# N32G05x register map
Vendor: Nationstech Ltd.; File version: 1.0
Registers are 32-bit, read-write, reset 0x0 unless marked. A register's access mark holds for its fields unless they carry their own. Offsets are from the block's base; [hi:lo] are bit positions; {n}, {i} and the like mark numbered series.

## AFIO — Alternate function I/O
Base 0x40010000
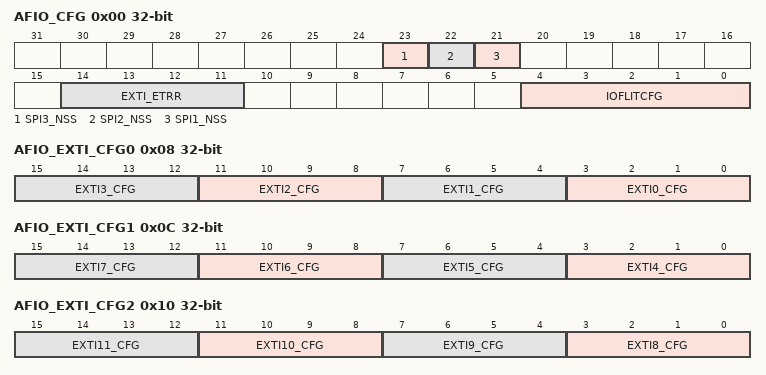
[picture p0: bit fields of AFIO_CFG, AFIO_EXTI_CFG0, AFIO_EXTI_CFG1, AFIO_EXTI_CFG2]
0x00 AFIO_CFG (reset mask 0xFFF800)
  [23] SPI3_NSS, [22] SPI2_NSS, [21] SPI1_NSS, [14:11] EXTI_ETRR, [4:0] IOFLITCFG
0x08 AFIO_EXTI_CFG0
  [4n+3:4n] EXTI{n}_CFG (n=0..3)
0x0C AFIO_EXTI_CFG1
  [4n-13:4n-16] EXTI{n}_CFG (n=4..7)
0x10 AFIO_EXTI_CFG2
  [4n-29:4n-32] EXTI{n}_CFG (n=8..11)
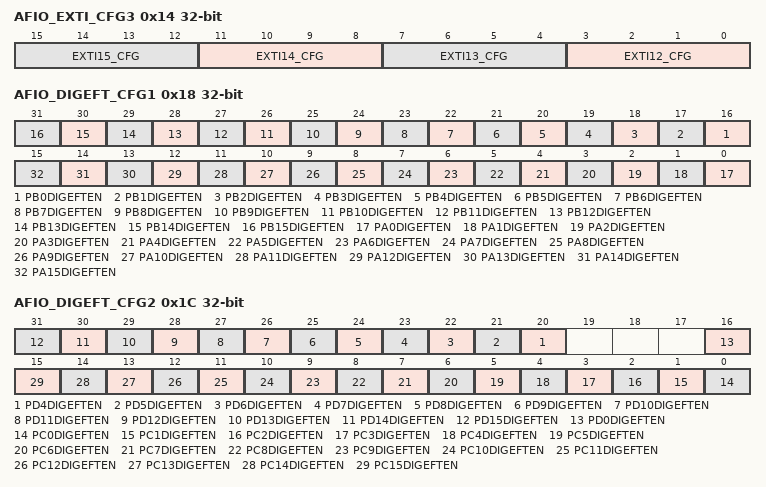
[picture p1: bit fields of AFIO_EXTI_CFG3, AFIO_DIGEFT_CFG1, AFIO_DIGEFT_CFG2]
0x14 AFIO_EXTI_CFG3
  [4n-45:4n-48] EXTI{n}_CFG (n=12..15)
0x18 AFIO_DIGEFT_CFG1
  [n+16] PB{n}DIGEFTEN (n=0..15), [n] PA{n}DIGEFTEN (n=0..15)
0x1C AFIO_DIGEFT_CFG2
  [n+16] PD{n}DIGEFTEN (n=4..15), [16] PD0DIGEFTEN, [n] PC{n}DIGEFTEN (n=0..15)

## I2C1 — Inter integrated circuit
Base 0x40005400
Same registers: I2C2 0x40005800
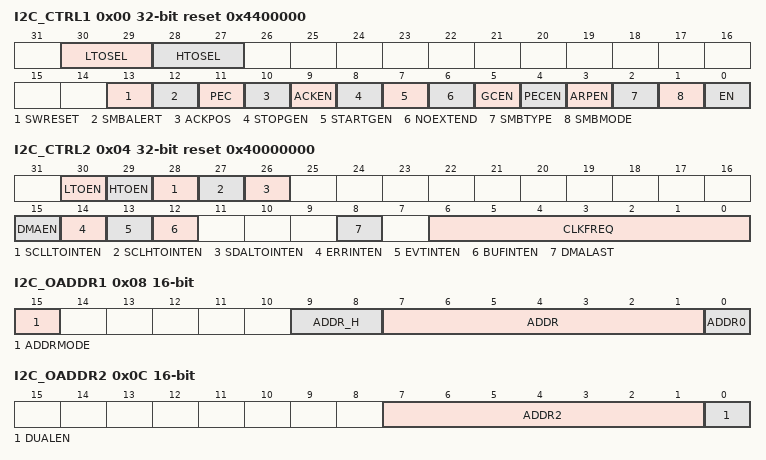
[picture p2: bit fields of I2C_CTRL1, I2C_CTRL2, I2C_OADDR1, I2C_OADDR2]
0x00 I2C_CTRL1 reset 0x4400000
  [30:29] LTOSEL, [28:27] HTOSEL, [13] SWRESET, [12] SMBALERT, [11] PEC, [10] ACKPOS, [9] ACKEN, [8] STOPGEN, [7] STARTGEN, [6] NOEXTEND, [5] GCEN, [4] PECEN, [3] ARPEN, [2] SMBTYPE, [1] SMBMODE, [0] EN
0x04 I2C_CTRL2 reset 0x40000000
  [30] LTOEN, [29] HTOEN, [28] SCLLTOINTEN, [27] SCLHTOINTEN, [26] SDALTOINTEN, [15] DMAEN, [14] ERRINTEN, [13] EVTINTEN, [12] BUFINTEN, [8] DMALAST, [6:0] CLKFREQ
0x08 I2C_OADDR1 16-bit
  [15] ADDRMODE, [9:8] ADDR_H, [7:1] ADDR, [0] ADDR0
0x0C I2C_OADDR2 16-bit
  [7:1] ADDR2, [0] DUALEN
0x10 I2C_DAT 16-bit
  [7:0] DATA
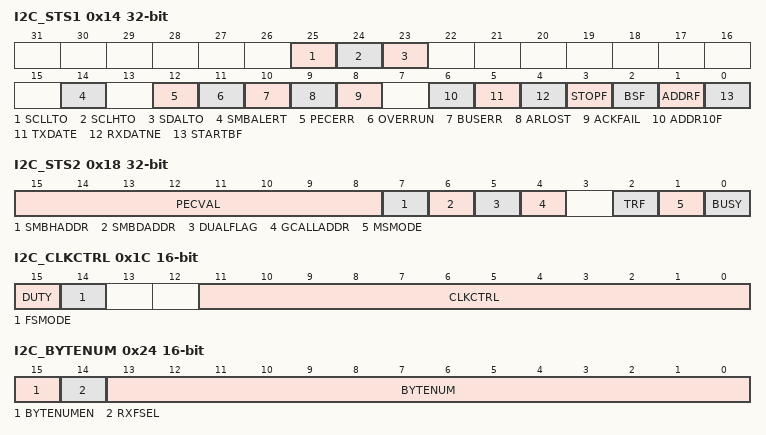
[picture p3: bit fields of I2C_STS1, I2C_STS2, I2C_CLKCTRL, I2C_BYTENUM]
0x14 I2C_STS1
  [25] SCLLTO, [24] SCLHTO, [23] SDALTO, [14] SMBALERT, [12] PECERR, [11] OVERRUN, [10] BUSERR, [9] ARLOST, [8] ACKFAIL, [6] ADDR10F, [5] TXDATE, [4] RXDATNE, [3] STOPF, [2] BSF, [1] ADDRF, [0] STARTBF
0x18 I2C_STS2
  [15:8] PECVAL, [7] SMBHADDR, [6] SMBDADDR, [5] DUALFLAG, [4] GCALLADDR, [2] TRF, [1] MSMODE, [0] BUSY
0x1C I2C_CLKCTRL 16-bit
  [15] DUTY, [14] FSMODE, [11:0] CLKCTRL
0x20 I2C_TMRISE 16-bit
  [5:0] TMRISE
0x24 I2C_BYTENUM 16-bit (reset mask 0xFF)
  [15] BYTENUMEN, [14] RXFSEL, [13:0] BYTENUM
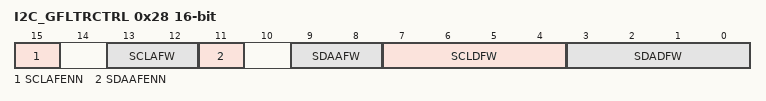
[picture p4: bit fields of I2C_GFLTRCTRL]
0x28 I2C_GFLTRCTRL 16-bit
  [15] SCLAFENN, [13:12] SCLAFW, [11] SDAAFENN, [9:8] SDAAFW, [7:4] SCLDFW, [3:0] SDADFW

## IWDG — Independent watchdog
Base 0x40003000
0x00 IWDG_KEY
  [15:0] KEYV
0x04 IWDG_PREDIV
  [2:0] PD
0x08 IWDG_RELV reset 0xFFF
  [11:0] REL
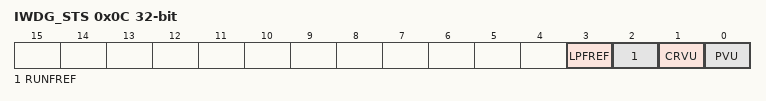
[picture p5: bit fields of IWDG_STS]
0x0C IWDG_STS (reset mask 0x3)
  [3] LPFREF, [2] RUNFREF, [1] CRVU, [0] PVU
0x10 IWDG_FREEZE
  [15:0] LPRERV

## LCD — Liquid Crystal Display
Base 0x40003C00
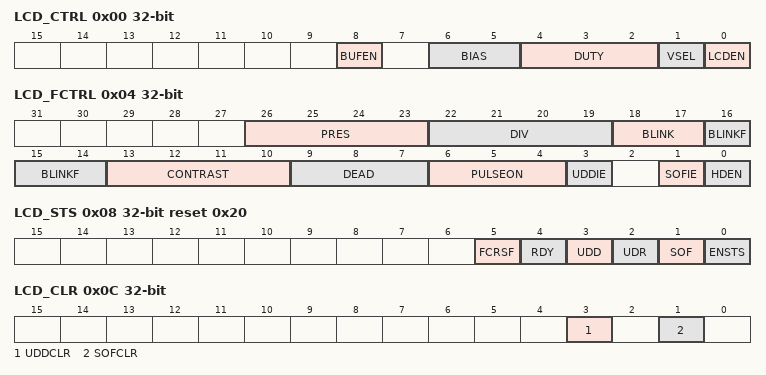
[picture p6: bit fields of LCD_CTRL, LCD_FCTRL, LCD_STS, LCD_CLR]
0x00 LCD_CTRL
  [8] BUFEN, [6:5] BIAS, [4:2] DUTY, [1] VSEL, [0] LCDEN
0x04 LCD_FCTRL (reset mask 0x7FFFFBF)
  [26:23] PRES, [22:19] DIV, [18:17] BLINK, [16:14] BLINKF, [13:10] CONTRAST, [9:7] DEAD, [6:4] PULSEON, [3] UDDIE, [1] SOFIE, [0] HDEN
0x08 LCD_STS reset 0x20
  [5] FCRSF, [4] RDY, [3] UDD, [2] UDR, [1] SOF, [0] ENSTS
0x0C LCD_CLR
  [3] UDDCLR, [1] SOFCLR
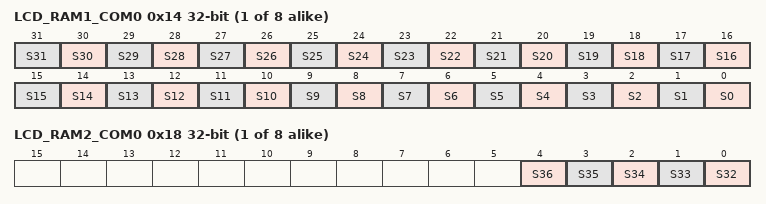
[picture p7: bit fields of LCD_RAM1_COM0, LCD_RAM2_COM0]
{0x14+8i} LCD_RAM1_COM{i} (i=0..7)
  [n] S{n} (n=0..31)
{0x18+8i} LCD_RAM2_COM{i} (i=0..7)
  [n-32] S{n} (n=32..36)

## PWR — Power control
Base 0x40007000
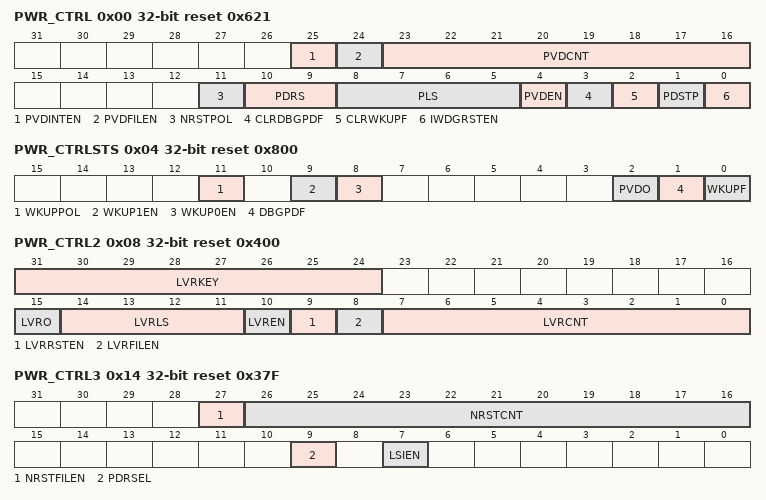
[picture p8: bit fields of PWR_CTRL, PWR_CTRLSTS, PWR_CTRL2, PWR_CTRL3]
0x00 PWR_CTRL reset 0x621 (reset mask 0x7FE)
  [25] PVDINTEN, [24] PVDFILEN, [23:16] PVDCNT, [11] NRSTPOL, [10:9] PDRS, [8:5] PLS, [4] PVDEN, [3] CLRDBGPDF, [2] CLRWKUPF, [1] PDSTP, [0] IWDGRSTEN
0x04 PWR_CTRLSTS reset 0x800
  [11] WKUPPOL, [9] WKUP1EN, [8] WKUP0EN, [2] PVDO, [1] DBGPDF, [0] WKUPF
0x08 PWR_CTRL2 reset 0x400 (reset mask 0x400)
  [31:24] LVRKEY, [15] LVRO, [14:11] LVRLS, [10] LVREN, [9] LVRRSTEN, [8] LVRFILEN, [7:0] LVRCNT
0x14 PWR_CTRL3 reset 0x37F (reset mask 0x80)
  [27] NRSTFILEN, [26:16] NRSTCNT, [9] PDRSEL, [7] LSIEN
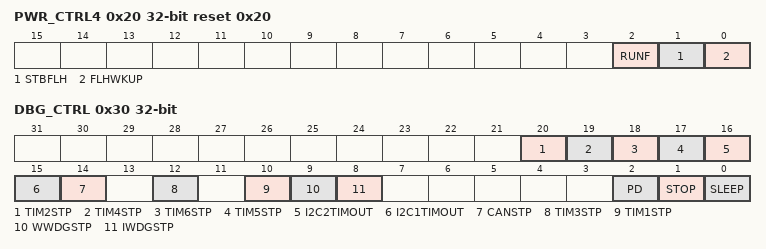
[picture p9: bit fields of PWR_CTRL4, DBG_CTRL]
0x20 PWR_CTRL4 reset 0x20 (reset mask 0x73)
  [2] RUNF, [1] STBFLH, [0] FLHWKUP
0x24 PWR_CTRL5 reset 0x4 (reset mask 0xC0)
  [3:2] STPMRSEL
0x28 PWR_CTRL6 (reset mask 0xC0)
  [3:2] STPMREN
0x30 DBG_CTRL (reset mask 0x79F06)
  [20] TIM2STP, [19] TIM4STP, [18] TIM6STP, [17] TIM5STP, [16] I2C2TIMOUT, [15] I2C1TIMOUT, [14] CANSTP, [12] TIM3STP, [10] TIM1STP, [9] WWDGSTP, [8] IWDGSTP, [2] PD, [1] STOP, [0] SLEEP
